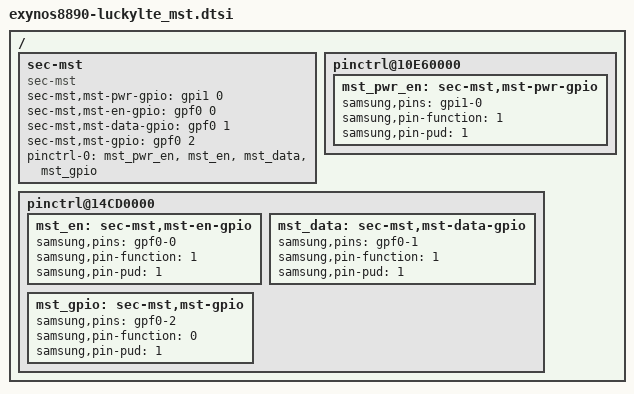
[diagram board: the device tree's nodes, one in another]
/* Copyright (c) 2013, Samsung Electronics Corporation. All rights reserved.
 *
 * This program is free software; you can redistribute it and/or modify
 * it under the terms of the GNU General Public License version 2 and
 * only version 2 as published by the Free Software Foundation.
 *
 * This program is distributed in the hope that it will be useful,
 * but WITHOUT ANY WARRANTY; without even the implied warranty of
 * MERCHANTABILITY or FITNESS FOR A PARTICULAR PURPOSE.  See the
 * GNU General Public License for more details.
 */

/ {
	sec-mst{
		compatible = "sec-mst";
		sec-mst,mst-pwr-gpio = <&gpi1 0 0>;
		sec-mst,mst-en-gpio = <&gpf0 0 0>;
		sec-mst,mst-data-gpio = <&gpf0 1 0>;
		sec-mst,mst-gpio = <&gpf0 2 0>;

		pinctrl-names = "default";
		pinctrl-0 = <&mst_pwr_en &mst_en &mst_data &mst_gpio>;
	};
	
	pinctrl@10E60000 {
		mst_pwr_en: sec-mst,mst-pwr-gpio {
			samsung,pins ="gpi1-0";
			samsung,pin-function = <1>;
			samsung,pin-pud = <1>;
		};
	};
	
	pinctrl@14CD0000 {
		mst_en: sec-mst,mst-en-gpio {
			samsung,pins ="gpf0-0";
			samsung,pin-function = <1>;
			samsung,pin-pud = <1>;
		};

		mst_data: sec-mst,mst-data-gpio {
			samsung,pins ="gpf0-1";
			samsung,pin-function = <1>;
			samsung,pin-pud = <1>;
		};

		mst_gpio: sec-mst,mst-gpio {
			samsung,pins ="gpf0-2";
			samsung,pin-function = <0>;
			samsung,pin-pud = <1>;
		};
	};
};
